# EFR32MG24B310F1536IM48 register map
Vendor: Silicon Labs; Series: EFR32; File version: B
Registers are 32-bit, read-write, reset 0x0 unless marked. A register's access mark holds for its fields unless they carry their own. Offsets are from the block's base; [hi:lo] are bit positions; {n}, {i} and the like mark numbered series; 'fields as' and 'values as' point back to an identical list.

## MVP_NS — MVP_NS Registers
Base 0x5D000000
Same registers: MVP_S 0x4D000000
0x00 IPVERSION ro reset 0x1
  [31:0] IPVERSION — IP Version ID
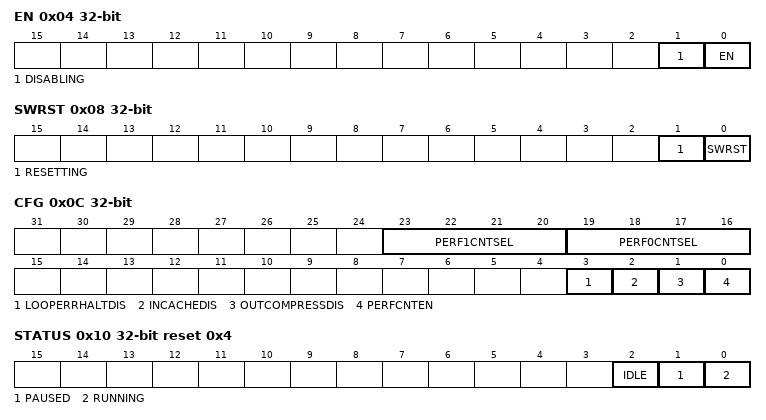
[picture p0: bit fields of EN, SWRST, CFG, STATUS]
0x04 EN — Block Enable Register
  [1] DISABLING ro — Disablement Busy Status
  [0] EN — Enable
0x08 SWRST — Software Reset Register
  [1] RESETTING ro — Software Reset Busy Status
  [0] SWRST wo — Software Reset Command
0x0C CFG — Configuration Register
  [23:20] PERF1CNTSEL — Performance Counter Select
    0=RUN (Total run count); 1=CMD (Total Commands Issued); 2=STALL (Total stall count (at sequencer issue)); 3=NOOP (NOOP ALU Op counter); 4=ALUACTIVE (Count cycles that ALU is active (not stalled), excluding NOOPs); 5=PIPESTALL (Stalls caused by register and resource conflicts within the ALU.); 6=IOFENCESTALL (Count stall cycles caused by memory hazards); 7=LOAD0STALL (Count stall cycles when accessing memory from load stream 0); 8=LOAD1STALL (Count stall cycles when accessing memory from load stream 1); 9=STORESTALL (Count stall cycles when writing memory from store stream); 10=BUSSTALL (Count cycles where any of previous 3 events is occurring); 11=LOAD0AHBSTALL (All stall cycles on load bus 0 AHB interface); 12=LOAD1AHBSTALL (All stall cycles on load bus 1 AHB interface); 13=LOAD0FENCESTALL (LOAD0 Fence Stall cycles); 14=LOAD1FENCESTALL (LOAD1 Fence Stall cycles)
  [19:16] PERF0CNTSEL — Performance Counter Select
    values as PERF1CNTSEL
  [3] LOOPERRHALTDIS — Loop Error Halt Disable
  [2] INCACHEDIS — ALU Input Word Cache Disable
  [1] OUTCOMPRESSDIS — ALU Output Stream Compression Disable
  [0] PERFCNTEN — Performance Counter Enable
0x10 STATUS ro reset 0x4
  [2] IDLE — Idle Status
  [1] PAUSED — Paused Status
  [0] RUNNING — Running Status
0x14 PERF0CNT ro — Run Counter
  [23:0] COUNT — Performance Counter
0x18 PERF1CNT ro — Run Counter
  [23:0] COUNT — Performance Counter
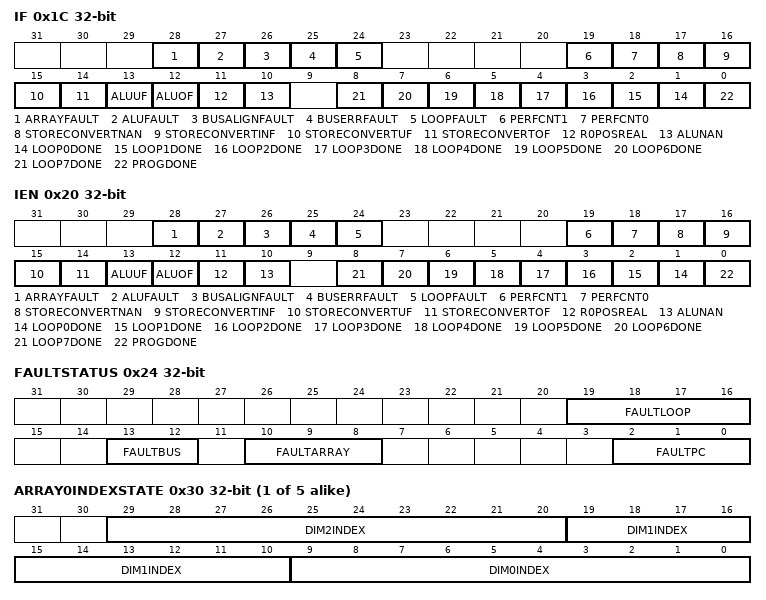
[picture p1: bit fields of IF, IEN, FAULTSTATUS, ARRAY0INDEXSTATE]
0x1C IF — Interrupt Flags
  [28] ARRAYFAULT — Array Fault Interrupt Flag
  [27] ALUFAULT — ALU Fault Interrupt Flag
  [26] BUSALIGNFAULT — Bus Alignment Fault Interrupt Flag
  [25] BUSERRFAULT — Bus Error Fault Interrupt Flag
  [24] LOOPFAULT — Loop Fault Interrupt Flag
  [19] PERFCNT1 — Stall Count Overflow Interrupt Flag
  [18] PERFCNT0 — Run Count Overflow Interrupt Flag
  [17] STORECONVERTNAN — NaN encountered during array store conversion
  [16] STORECONVERTINF — Infinity encountered during array store conversion
  [15] STORECONVERTUF — Underflow during array store conversion
  [14] STORECONVERTOF — Overflow during array store
  [13] ALUUF — ALU Underflow on result
  [12] ALUOF — ALU Overflow on result
  [11] R0POSREAL — R0 non-zero Interrupt Flag
  [10] ALUNAN — Not-a-Number Interrupt Flag
  [n+1] LOOP{n}DONE (n=0..7) — Loop Done Interrupt Flag
  [0] PROGDONE — Program Done Interrupt Flags
0x20 IEN — Interrupt Enable
  [28] ARRAYFAULT — Array Fault Interrupt Enable
  [27] ALUFAULT — ALU Input Fault Interrupt Enable
  [26] BUSALIGNFAULT — Bus Alignment Fault Interrupt Enable
  [25] BUSERRFAULT — Bus Error Fault Interrupt Enable
  [24] LOOPFAULT — Loop Fault Interrupt Enable
  [19] PERFCNT1 — Perf Counter 1 Overflow Interrupt Enable
  [18] PERFCNT0 — Perf Counter 0 Overflow Interrupt Enable
  [17] STORECONVERTNAN — Store Conversion NaN Interrupt Enable
  [16] STORECONVERTINF — Store Conversion Infinity Interrupt Enable
  [15] STORECONVERTUF — Store Conversion Underflow Interrupt Enable
  [14] STORECONVERTOF — Store conversion Overflow Interrupt Enable
  [13] ALUUF — ALU Underflow Interrupt Enable
  [12] ALUOF — ALU Overflow Interrupt Enable
  [11] R0POSREAL — R0 Non-Zero Interrupt Enable
  [10] ALUNAN — Not-a-Number Interrupt Enable
  [n+1] LOOP{n}DONE (n=0..7) — Loop Done Interrupt Enable
  [0] PROGDONE — Program Done Interrupt Enable
0x24 FAULTSTATUS ro
  [19:16] FAULTLOOP — Loop Fault Indicator
  [13:12] FAULTBUS — Bus where fault occurred
    0=NONE; 1=LOAD0STREAM; 2=LOAD1STREAM; 3=STORESTREAM
  [10:8] FAULTARRAY — Array access that generated a fault
  [2:0] FAULTPC — PC when fault occurred
0x28 FAULTADDR ro — Fault Address Register
  [31:0] FAULTADDR — Bus Fault Address Register
0x2C PROGRAMSTATE
  [2:0] PC — Program Counter
{0x30+4i} ARRAY{i}INDEXSTATE (i=0..4) — Array N Index State Register
  [29:20] DIM2INDEX — Current Index
  [19:10] DIM1INDEX — Current Index
  [9:0] DIM0INDEX — Current Index
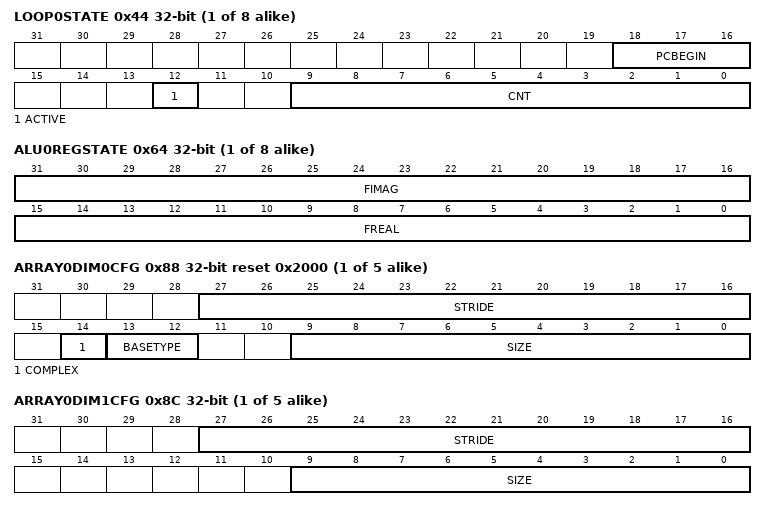
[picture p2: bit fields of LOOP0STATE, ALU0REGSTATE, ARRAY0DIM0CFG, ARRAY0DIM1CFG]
{0x44+4i} LOOP{i}STATE (i=0..7) — Loop N State Register
  [18:16] PCBEGIN — Loop Start
  [12] ACTIVE — Loop Active
  [9:0] CNT — Loop Counter
{0x64+4i} ALU{i}REGSTATE (i=0..7) — ALU Register
  [31:16] FIMAG — Float Imaginary Value
  [15:0] FREAL — Float Real Value
{0x84+0x10*i} ARRAY{i}ADDRCFG (i=0..4) — Array N Base Address Register
  [31:0] BASE — Array Base Address
{0x88+0x10*i} ARRAY{i}DIM0CFG reset 0x2000 (i=0..4) — Array N Dimenion 0 Configuration
  [27:16] STRIDE — Dimension Stride Step
  [14] COMPLEX — Complex Data Type
    0=SCALAR (Data represents a scalar number); 1=COMPLEX (Data represents a complex pair or packed pair of reals.)
  [13:12] BASETYPE — Element Type
    0=UINT8 (Data is unsigned 8-bit integer (can only be used for loads)); 1=INT8 (Data is signed 8-bit integer (can only be used for loads)); 2=BINARY16 (Data is 16-bit float)
  [9:0] SIZE — Array Dimension Size
{0x8C+0x10*i} ARRAY{i}DIM1CFG (i=0..4) — Array N Dimenion 1 Configuration
  [27:16] STRIDE — Dimension Stride Step
  [9:0] SIZE — Array Dimension Size
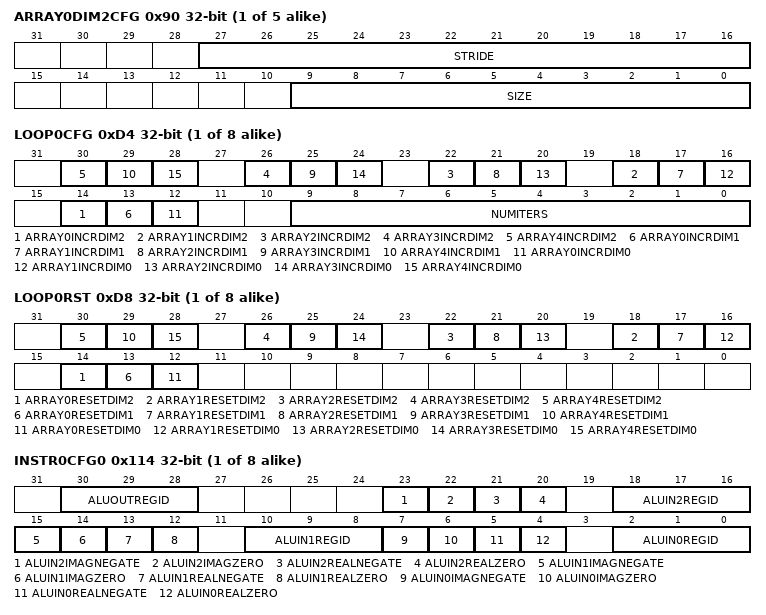
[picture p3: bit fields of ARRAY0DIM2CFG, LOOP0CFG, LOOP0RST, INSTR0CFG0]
{0x90+0x10*i} ARRAY{i}DIM2CFG (i=0..4) — Array N Dimenion 2 Configuration
  fields as ARRAY0DIM1CFG
{0xD4+8i} LOOP{i}CFG (i=0..7) — Loop N Configuration Register
  [4n+14] ARRAY{n}INCRDIM2 (n=0..4) — Increment Dimension 2
  [4n+13] ARRAY{n}INCRDIM1 (n=0..4) — Increment Dimension 1
  [4n+12] ARRAY{n}INCRDIM0 (n=0..4) — Increment Dimension 0
  [9:0] NUMITERS — Number of Iterations
{0xD8+8i} LOOP{i}RST (i=0..7) — Loop N Reset Configuration Register
  [4n+14] ARRAY{n}RESETDIM2 (n=0..4) — Reset Dimension 2
  [4n+13] ARRAY{n}RESETDIM1 (n=0..4) — Reset Dimension 1
  [4n+12] ARRAY{n}RESETDIM0 (n=0..4) — Reset Dimension 0
{0x114+0xC*i} INSTR{i}CFG0 (i=0..7) — Instruction N Word 0
  [30:28] ALUOUTREGID — Register ID
  [23] ALUIN2IMAGNEGATE — Imaginary Negate
  [22] ALUIN2IMAGZERO — Imaginary Not Zero
  [21] ALUIN2REALNEGATE — Real Negate
  [20] ALUIN2REALZERO — Real Zero
  [18:16] ALUIN2REGID — Register ID
  [15] ALUIN1IMAGNEGATE — Imaginary Negate
  [14] ALUIN1IMAGZERO — Imaginary Not Zero
  [13] ALUIN1REALNEGATE — Real Negate
  [12] ALUIN1REALZERO — Real Zero
  [10:8] ALUIN1REGID — Register ID
  [7] ALUIN0IMAGNEGATE — Imaginary Negate
  [6] ALUIN0IMAGZERO — Imaginary Not Zero
  [5] ALUIN0REALNEGATE — Real Negate
  [4] ALUIN0REALZERO — Real Zero
  [2:0] ALUIN0REGID — Register ID
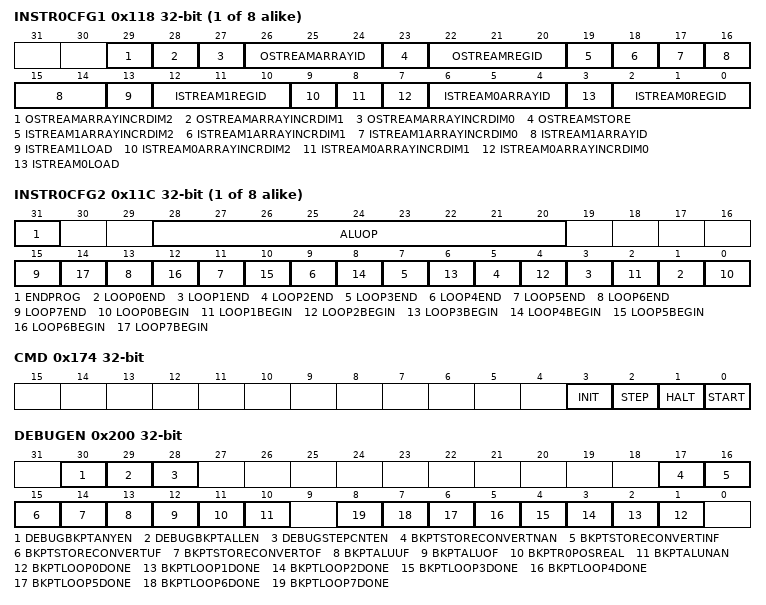
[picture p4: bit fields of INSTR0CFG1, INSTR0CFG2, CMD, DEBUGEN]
{0x118+0xC*i} INSTR{i}CFG1 (i=0..7) — Instruction N word 1
  [29] OSTREAMARRAYINCRDIM2 — Increment Array Dimension 2
  [28] OSTREAMARRAYINCRDIM1 — Increment Array Dimension 1
  [27] OSTREAMARRAYINCRDIM0 — Increment Array Dimension 0
  [26:24] OSTREAMARRAYID — Array ID
  [23] OSTREAMSTORE — Store to Register
  [22:20] OSTREAMREGID — Register ID
  [19] ISTREAM1ARRAYINCRDIM2 — Increment Array Dimension 2
  [18] ISTREAM1ARRAYINCRDIM1 — Increment Array Dimension 1
  [17] ISTREAM1ARRAYINCRDIM0 — Increment Array Dimension 0
  [16:14] ISTREAM1ARRAYID — Array ID
  [13] ISTREAM1LOAD — Load register
  [12:10] ISTREAM1REGID — Register ID
  [9] ISTREAM0ARRAYINCRDIM2 — Increment Array Dimension 2
  [8] ISTREAM0ARRAYINCRDIM1 — Increment Array Dimension 1
  [7] ISTREAM0ARRAYINCRDIM0 — Increment Array Dimension 0
  [6:4] ISTREAM0ARRAYID — Array ID
  [3] ISTREAM0LOAD — Load register
  [2:0] ISTREAM0REGID — Register ID
{0x11C+0xC*i} INSTR{i}CFG2 (i=0..7) — Instruction N word 2
  [31] ENDPROG — End of Program
  [28:20] ALUOP — ALU opcode
    0=NOOP (No Operation); 1=CLEAR (Clear register (set to +0)); 65=COPY (Copy operation); 66=SWAP (Swap operation); 67=DBL (Double operation (multiply by 2)); 68=FANA (Load real and imag (form A)); 69=FANB (Load real and imag (form B)); 70=RELU2 (ReLU of real (max of real and +0)); 71=NRELU2 (Min of real and -0); 72=INC2 (Increment by 1.0); 73=DEC2 (Decrement by 1.0); 74=ADDR (Addition of 2 reals); 75=MAX (Maximum of 2 reals); 76=MIN (Minimum of 2 reals); 0x124=RSQR2B (Square of real (form B)); 0x14E=ADDC (Add Complex); 0x153=MAX2A (Max of reals (form A)); 0x154=MIN2A (Min of reals (form A)); 0x15E=XREALC2 (Extract real from complex); 0x15F=XIMAGC2 (Extract imag from complex); 0x161=ADDR2B (Add reals (form B)); 0x162=MAX2B (Max of reals (form B)); 0x163=MIN2B (Min of reals (form B)); 0x18D=MULC (Multiply Complex); 0x197=MULR2A (Multiply reals (form A)); 0x198=MULR2B (Multiply reals (form B)); 0x19A=ADDR4 (Add 4 reals); 0x19B=MAX4 (Max of 4 reals); 0x19C=MIN4 (Min of 4 reals); 0x19D=SQRMAGC2 (Squared magnitude Complex); 0x1A0=PRELU2B (Parametric ReLU (form B)); 0x1CD=MACC (Multiply Accumulate Complex); 0x1CE=AACC (Add Accumulate Complex); 0x1CF=ELU2A (part of ELU activation (form A)); 0x1D0=ELU2B (part of ELU activation (form B)); 0x1D1=IFR2A (If A then X else Y (form A)); 0x1D2=IFR2B (If A then X else Y (form B)); 0x1D3=MAXAC2 (Max of reals and accumulator); 0x1D4=MINAC2 (Min of reals and accumulators); 0x1D5=CLIP2A (Clipping activation (form A)); 0x1D6=CLIP2B (Clipping activation (form B)); 0x1D7=MACR2A (Multiply accumulate reals (form A)); 0x1D8=MACR2B (Multiply accumulate reals (form B)); 0x1D9=IFC (If A then X else Y (complex))
  [2n+1] LOOP{n}END (n=0..7) — Loop End
  [2n] LOOP{n}BEGIN (n=0..7) — Loop Begin
0x174 CMD wo — Command Register
  [3] INIT — Initialization Command/Qualifier
  [2] STEP — Step Command
  [1] HALT — Halt Command
  [0] START — Start Command
0x200 DEBUGEN — Debug Control Register
  [30] DEBUGBKPTANYEN — Enable Breakpoint when ANY conditions match
  [29] DEBUGBKPTALLEN — Trigger Breakpoint when ALL conditions match
  [28] DEBUGSTEPCNTEN — Debug Step Count Enable
  [17] BKPTSTORECONVERTNAN — Enable Breakpoint on STORECONVERTNAN
  [16] BKPTSTORECONVERTINF — Enable Breakpoint on STORECONVERTINF
  [15] BKPTSTORECONVERTUF — Enable Breakpoint on STORECONVERTUF
  [14] BKPTSTORECONVERTOF — Enable Breakpoint on STORECONVERTOF
  [13] BKPTALUUF — Enable Breakpoint on ALUUF
  [12] BKPTALUOF — Enable Breakpoint on ALUOF
  [11] BKPTR0POSREAL — Enable Breakpoint on R0POSREAL
  [10] BKPTALUNAN — Enable Breakpoint on ALUNAN
  [n+1] BKPTLOOP{n}DONE (n=0..7) — Enable Breakpoint on Loop Done
0x204 DEBUGSTEPCNT
  [23:0] DEBUGSTEPCNT — Debug Step Counter
